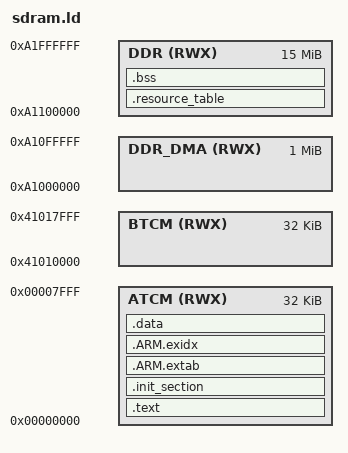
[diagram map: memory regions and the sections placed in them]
/****************************************************************************
 * boards/arm/am67/beagley-ai/scripts/sdram.ld
 *
 * SPDX-License-Identifier: Apache-2.0
 *
 * Licensed to the Apache Software Foundation (ASF) under one or more
 * contributor license agreements.  See the NOTICE file distributed with
 * this work for additional information regarding copyright ownership.  The
 * ASF licenses this file to you under the Apache License, Version 2.0 (the
 * "License"); you may not use this file except in compliance with the
 * License.  You may obtain a copy of the License at
 *
 *   http://www.apache.org/licenses/LICENSE-2.0
 *
 * Unless required by applicable law or agreed to in writing, software
 * distributed under the License is distributed on an "AS IS" BASIS, WITHOUT
 * WARRANTIES OR CONDITIONS OF ANY KIND, either express or implied.  See the
 * License for the specific language governing permissions and limitations
 * under the License.
 *
 ****************************************************************************/
MEMORY
{
    /* ATCM and BTCM for Main R5FSS Core 0 (addresses based on TI J722S TRM) */
    ATCM                 (RWX) : ORIGIN = 0x0, LENGTH = 32K
    BTCM                 (RWX) : ORIGIN = 0x41010000, LENGTH = 32K

    /* DDR regions from device tree for mcu_r5fss0_core0 */
    DDR_DMA              (RWX) : ORIGIN = 0xa1000000, LENGTH = 1M   /* mcu_r5fss0_core0_dma_memory_region */
    DDR                  (RWX) : ORIGIN = 0xa1100000, LENGTH = 15M  /* mcu_r5fss0_core0_memory_region */
}

EXTERN(_vectors)
ENTRY(_stext)

SECTIONS
{
    .text : {
        _stext = ABSOLUTE(.);
        *(.vectors)
        *(.text .text.*)
        *(.fixup)
        *(.gnu.warning)
        *(.rodata .rodata.*)
        *(.gnu.linkonce.t.*)
        *(.glue_7)
        *(.glue_7t)
        *(.got)
        *(.gcc_except_table)
        *(.gnu.linkonce.r.*)
        _etext = ABSOLUTE(.);
    } > ATCM

    .resource_table :
    {
        KEEP(*(.resource_table))
        . = ALIGN(1024);
    } > DDR
    
    .init_section : {
        _sinit = ABSOLUTE(.);
        KEEP(*(SORT_BY_INIT_PRIORITY(.init_array.*) SORT_BY_INIT_PRIORITY(.ctors.*)))
        KEEP(*(.init_array EXCLUDE_FILE(*crtbegin.o *crtbegin?.o *crtend.o *crtend?.o) .ctors))
        _einit = ABSOLUTE(.);
    } > ATCM

    .ARM.extab : {
        *(.ARM.extab*)
    } > ATCM

    __exidx_start = ABSOLUTE(.);
    .ARM.exidx : {
        *(.ARM.exidx*)
    } > ATCM
    __exidx_end = ABSOLUTE(.);

    _eronly = ABSOLUTE(.);

    .data : {
        _sdata = ABSOLUTE(.);
        *(.data .data.*)
        *(.gnu.linkonce.d.*)
        CONSTRUCTORS
        . = ALIGN(4);
        _edata = ABSOLUTE(.);
    } > ATCM

    .bss : {
        _sbss = ABSOLUTE(.);
        *(.bss .bss.*)
        *(.gnu.linkonce.b.*)
        *(COMMON)
        . = ALIGN(4);
        _ebss = ABSOLUTE(.);
    } > DDR

    /* Stabs debugging sections. */
    .stab 0 : { *(.stab) }
    .stabstr 0 : { *(.stabstr) }
    .stab.excl 0 : { *(.stab.excl) }
    .stab.exclstr 0 : { *(.stab.exclstr) }
    .stab.index 0 : { *(.stab.index) }
    .stab.indexstr 0 : { *(.stab.indexstr) }
    .comment 0 : { *(.comment) }
    .debug_abbrev 0 : { *(.debug_abbrev) }
    .debug_info 0 : { *(.debug_info) }
    .debug_line 0 : { *(.debug_line) }
    .debug_pubnames 0 : { *(.debug_pubnames) }
    .debug_aranges 0 : { *(.debug_aranges) }
}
